# FM33LE0XXA register map
File version: 1.0
CPU: SC000 r1p0, little endian, no MPU, no FPU, 3 interrupt priority bits
Registers are 32-bit, read-write, reset 0x0 unless marked. A register's access mark holds for its fields unless they carry their own. Offsets are from the block's base; [hi:lo] are bit positions.

## UART2 — UART2 module information
Base 0x40013000
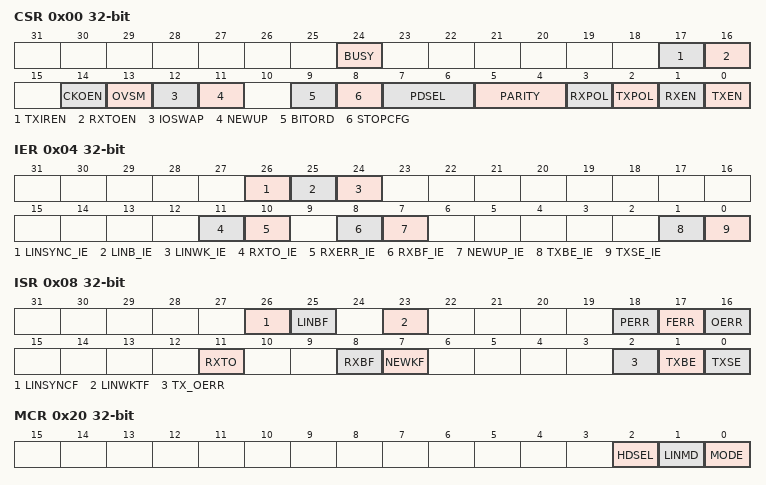
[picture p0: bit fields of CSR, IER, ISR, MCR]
0x00 CSR access per field — UART2 Control Status Register
  [24] BUSY ro — BUSY field description
  [17] TXIREN rw — TXIREN field description
  [16] RXTOEN rw — RXTOEN field description
  [14] CKOEN rw — CKOEN field description
  [13] OVSM rw — OVSM field description
  [12] IOSWAP rw — IOSWAP field description
  [11] NEWUP rw — NEWUP field description
  [9] BITORD rw — BITORD field description
  [8] STOPCFG rw — STOPCFG field description
  [7:6] PDSEL rw — PDSEL field description
  [5:4] PARITY rw — PARITY field description
  [3] RXPOL rw — RXPOL field description
  [2] TXPOL rw — TXPOL field description
  [1] RXEN rw — RXEN field description
  [0] TXEN rw — TXEN field description
0x04 IER — UART2 Interrupt Enable Register
  [26] LINSYNC_IE — LINSYNC_IE field description
  [25] LINB_IE — LINB_IE field description
  [24] LINWK_IE — LINWK_IE field description
  [11] RXTO_IE — RXTO_IE field description
  [10] RXERR_IE — RXERR_IE field description
  [8] RXBF_IE — RXBF_IE field description
  [7] NEWUP_IE — NEWUP_IE field description
  [1] TXBE_IE — TXBE_IE field description
  [0] TXSE_IE — TXSE_IE field description
0x08 ISR access per field — UART2 Interrupt Status Register
  [26] LINSYNCF rw — LINSYNCF field description
  [25] LINBF rw — LINBF field description
  [23] LINWKTF rw — LINWKTF field description
  [18] PERR rw — PERR field description
  [17] FERR rw — FERR field description
  [16] OERR rw — OERR field description
  [11] RXTO rw — RXTO field description
  [8] RXBF rw — RXBF field description
  [7] NEWKF rw — NEWKF field description
  [2] TX_OERR rw — TX_OERR field description
  [1] TXBE ro — TXBE field description
  [0] TXSE rw — TXSE field description
0x10 RXBUF ro — UART2 Receive Buffer
  [8:0] RXBUF — RXBUF field description
0x14 TXBUF wo — UART2Transmit Buffer
  [8:0] TXBUF — TXBUF field description
0x18 BGR reset 0x341 — UART2 Baud rate Generator Register
  [15:0] SPBRG — SPBRG field description
0x20 MCR — UART2 Mode Control Register
  [2] HDSEL — HDSEL field description
  [1] LINMD — LINMD field description
  [0] MODE — MODE field description
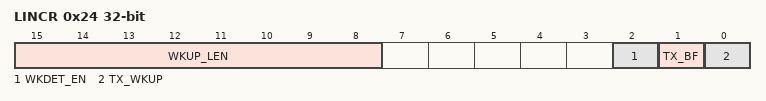
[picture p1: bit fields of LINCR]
0x24 LINCR
  [15:8] WKUP_LEN — WKUP_LEN field description
  [2] WKDET_EN — WKDET_EN field description
  [1] TX_BF — TX_BF field description
  [0] TX_WKUP — TX_WKUP field description
0x28 LINBSR ro
  [19:0] BAUD_SYNC — BAUD_SYNC field description

## LPUART0 — LPUART0 module information
Base 0x40010400
Same registers: LPUART1 0x40018400
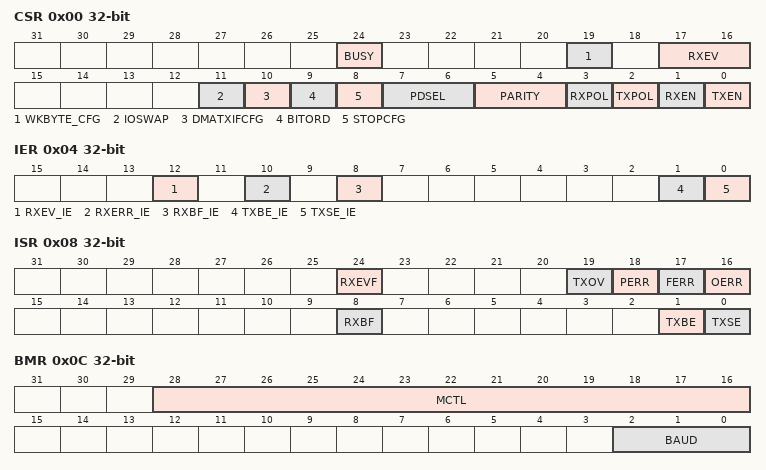
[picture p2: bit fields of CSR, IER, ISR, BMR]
0x00 CSR access per field — LPUART0 Control Status Register
  [24] BUSY ro — BUSY field description
  [19] WKBYTE_CFG rw — WKBYTE_CFG field description
  [17:16] RXEV rw — RXEV field description
  [11] IOSWAP rw — IOSWAP field description
  [10] DMATXIFCFG rw — DMATXIFCFG field description
  [9] BITORD rw — BITORD field description
  [8] STOPCFG rw — STOPCFG field description
  [7:6] PDSEL rw — PDSEL field description
  [5:4] PARITY rw — PARITY field description
  [3] RXPOL rw — RXPOL field description
  [2] TXPOL rw — TXPOL field description
  [1] RXEN rw — RXEN field description
  [0] TXEN rw — TXEN field description
0x04 IER — LPUART0 Interrupt Enable Register
  [12] RXEV_IE — RXEV_IE field description
  [10] RXERR_IE — RXERR_IE field description
  [8] RXBF_IE — RXBF_IE field description
  [1] TXBE_IE — TXBE_IE field description
  [0] TXSE_IE — TXSE_IE field description
0x08 ISR — LPUART0 Interrupt Status Register
  [24] RXEVF — RXEVF field description
  [19] TXOV — TXOV field description
  [18] PERR — PERR field description
  [17] FERR — FERR field description
  [16] OERR — OERR field description
  [8] RXBF — RXBF field description
  [1] TXBE — TXBE field description
  [0] TXSE — TXSE field description
0x0C BMR — LPUART0 Baud rate Modulation Register
  [28:16] MCTL — MCTL field description
  [2:0] BAUD — BAUD field description
0x10 RXBUF ro — LPUART0 Receive Buffer Register
  [8:0] RXBUF — RXBUF field description
0x14 TXBUF — LPUART0 Transmit Buffer Register
  [8:0] TXBUF — TXBUF field description
0x18 DMR — LPUART0 data Matching Register
  [8:0] MATD — MATD field description
